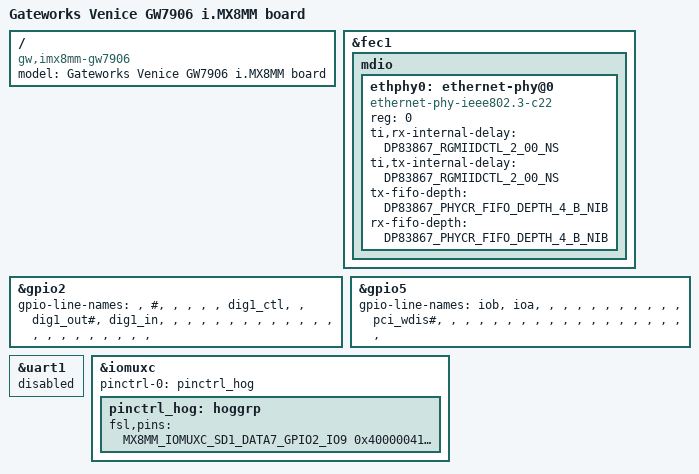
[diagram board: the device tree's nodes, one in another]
// SPDX-License-Identifier: (GPL-2.0+ OR MIT)
/*
 * Copyright 2025 Gateworks Corporation
 */

/dts-v1/;

#include <dt-bindings/net/ti-dp83867.h>

#include "imx8mm-venice-gw7903.dts"

/ {
	model = "Gateworks Venice GW7906 i.MX8MM board";
	compatible = "gw,imx8mm-gw7906", "fsl,imx8mm";
};

&fec1 {
	mdio {
		#address-cells = <1>;
		#size-cells = <0>;

		ethphy0: ethernet-phy@0 {
			compatible = "ethernet-phy-ieee802.3-c22";
			reg = <0>;
			ti,rx-internal-delay = <DP83867_RGMIIDCTL_2_00_NS>;
			ti,tx-internal-delay = <DP83867_RGMIIDCTL_2_00_NS>;
			tx-fifo-depth = <DP83867_PHYCR_FIFO_DEPTH_4_B_NIB>;
			rx-fifo-depth = <DP83867_PHYCR_FIFO_DEPTH_4_B_NIB>;
		};
	};
};

&gpio2 {
	gpio-line-names = "", "#", "", "", "", "", "dig1_ctl", "",
		"dig1_out#", "dig1_in", "", "", "", "", "", "",
		"", "", "", "", "", "", "", "",
		"", "", "", "", "", "", "", "";
};

&gpio5 {
	gpio-line-names = "iob", "ioa", "", "", "", "", "", "",
		"", "", "", "", "pci_wdis#", "", "", "",
		"", "", "", "", "", "", "", "",
		"", "", "", "", "", "", "", "";
};

&uart1 {
	status = "disabled";
};

&iomuxc {
	pinctrl-names = "default";
	pinctrl-0 = <&pinctrl_hog>;

	pinctrl_hog: hoggrp {
		fsl,pins = <
			MX8MM_IOMUXC_SD1_DATA7_GPIO2_IO9	0x40000041 /* DIG1_IN */
			MX8MM_IOMUXC_SD1_DATA6_GPIO2_IO8	0x40000041 /* DIG1_OUT */
			MX8MM_IOMUXC_SD1_DATA4_GPIO2_IO6	0x40000041 /* DIG1_CTL */
			MX8MM_IOMUXC_ECSPI2_MISO_GPIO5_IO12	0x40000041 /* PCI_WDIS# */
			MX8MM_IOMUXC_SAI3_TXD_GPIO5_IO1		0x40000041 /* IOA */
			MX8MM_IOMUXC_SAI3_TXC_GPIO5_IO0		0x40000041 /* IOB */
		>;
	};
};
